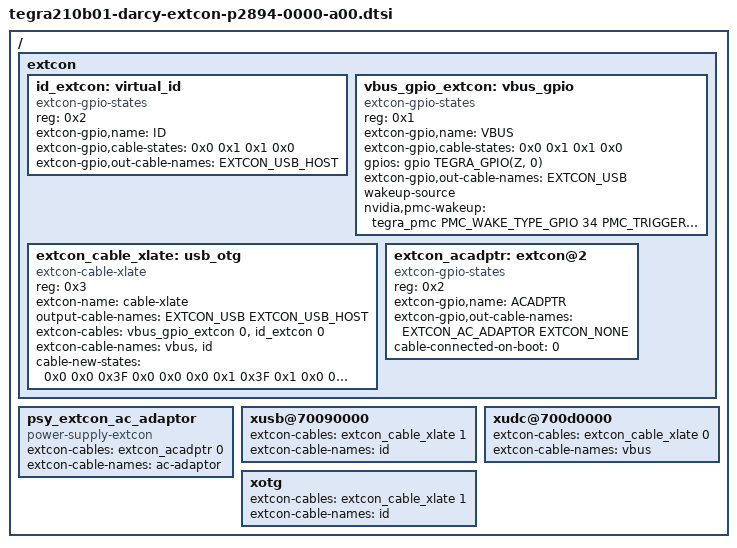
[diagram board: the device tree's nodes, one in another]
/*
 * Copyright (c) 2015-2016, NVIDIA CORPORATION.  All rights reserved.
 *
 * This program is free software; you can redistribute it and/or modify it
 * under the terms and conditions of the GNU General Public License,
 * version 2, as published by the Free Software Foundation.
 *
 * This program is distributed in the hope it will be useful, but WITHOUT
 * ANY WARRANTY; without even the implied warranty of MERCHANTABILITY or
 * FITNESS FOR A PARTICULAR PURPOSE.  See the GNU General Public License for
 * more details.
 */

#include "dt-bindings/extcon-ids.h"

/ {
	extcon {
		id_extcon: virtual_id {
			compatible = "extcon-gpio-states";
			reg = <0x2>;
			extcon-gpio,name = "ID";
			extcon-gpio,cable-states = <0x0 0x1
						0x1 0x0>;
			extcon-gpio,out-cable-names = <EXTCON_USB_HOST>;
			#extcon-cells = <1>;
		};

		vbus_gpio_extcon: vbus_gpio {
			compatible = "extcon-gpio-states";
			reg = <0x1>;
			extcon-gpio,name = "VBUS";
			extcon-gpio,cable-states = <0x0 0x1
						0x1 0x0>;
			gpios = <&gpio TEGRA_GPIO(Z, 0) 0>;
			extcon-gpio,out-cable-names = <EXTCON_USB>;
			wakeup-source;
			#extcon-cells = <1>;
			nvidia,pmc-wakeup = <&tegra_pmc
				PMC_WAKE_TYPE_GPIO 34 PMC_TRIGGER_TYPE_NONE>;
		};


		extcon_cable_xlate: usb_otg {
			compatible = "extcon-cable-xlate";
			reg = <0x3>;
			extcon-name = "cable-xlate";
			output-cable-names = <EXTCON_USB  EXTCON_USB_HOST>;
			extcon-cables = <&vbus_gpio_extcon 0 &id_extcon 0>;
			extcon-cable-names = "vbus", "id";
			cable-new-states = <0x0    0x0    0x3F    0x0    0x0
					0x0     0x1     0x3F    0x1   0x0
					0x0     0x2     0x3F    0x2   0x0
					0x2     0x3     0x3F    0x2   0x0
					0x2     0x1     0x3F    0x2   0x0
					0x1     0x0     0x3F    0x0   0x0
					0x3     0x0     0x3F    0x0   0x0
					0x3     0x1     0x3F    0x0   0x1
					0x2     0x0     0x3F    0x0   0x1
					0x1	0x3	0x3F	0x2   0x1>;
			#extcon-cells = <1>;
		};

		extcon_acadptr: extcon@2 {
			compatible = "extcon-gpio-states";
			reg = <0x2>;
			extcon-gpio,name = "ACADPTR";
			extcon-gpio,out-cable-names = <EXTCON_AC_ADAPTOR EXTCON_NONE>;
			cable-connected-on-boot = <0>;
			#extcon-cells = <1>;
		};
	};

	psy_extcon_ac_adaptor {
		compatible = "power-supply-extcon";
		extcon-cables = <&extcon_acadptr 0>;
		extcon-cable-names = "ac-adaptor";
		status = "okay";
	};


	xusb@70090000 {
		extcon-cables = <&extcon_cable_xlate 1>;
		extcon-cable-names = "id";
	};

	xudc@700d0000 {
		extcon-cables = <&extcon_cable_xlate 0>;
		extcon-cable-names = "vbus";
	};

	xotg {
		extcon-cables = <&extcon_cable_xlate 1>;
		extcon-cable-names = "id";
	};
};
